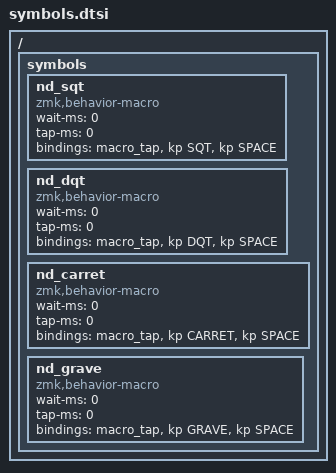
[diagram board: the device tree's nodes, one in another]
/ {
    symbols {
        nd_sqt: nd_sqt {
            wait-ms = <0>;
            tap-ms = <0>;
            compatible = "zmk,behavior-macro";
            #binding-cells = <0>;
            bindings = <&macro_tap &kp SQT &kp SPACE>;
        };
        nd_dqt: nd_dqt {
            wait-ms = <0>;
            tap-ms = <0>;
            compatible = "zmk,behavior-macro";
            #binding-cells = <0>;
            bindings = <&macro_tap &kp DQT &kp SPACE>;
        };
        nd_carret: nd_carret {
            wait-ms = <0>;
            tap-ms = <0>;
            compatible = "zmk,behavior-macro";
            #binding-cells = <0>;
            bindings = <&macro_tap &kp CARRET &kp SPACE>;
        };
        nd_grave: nd_grave {
            wait-ms = <0>;
            tap-ms = <0>;
            compatible = "zmk,behavior-macro";
            #binding-cells = <0>;
            bindings = <&macro_tap &kp GRAVE &kp SPACE>;
        };
    };
};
